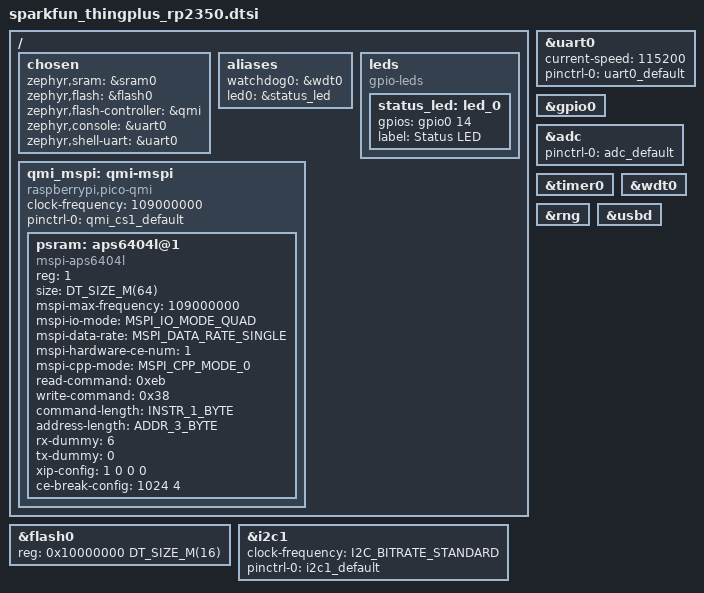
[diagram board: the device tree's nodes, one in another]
/*
 * SPDX-License-Identifier: Apache-2.0
 *
 * SparkFun Thing Plus RP2350 — common board configuration
 * (cpucluster-agnostic; included by both M33 and Hazard3 .dts files).
 */

#include <freq.h>
#include <zephyr/dt-bindings/i2c/i2c.h>
#include <zephyr/dt-bindings/pwm/pwm.h>
#include <zephyr/dt-bindings/gpio/gpio.h>

#include "sparkfun_thingplus_rp2350-pinctrl.dtsi"

/ {
	chosen {
		zephyr,sram = &sram0;
		zephyr,flash = &flash0;
		zephyr,flash-controller = &qmi;
		zephyr,console = &uart0;
		zephyr,shell-uart = &uart0;
	};

	aliases {
		watchdog0 = &wdt0;
		led0 = &status_led;
	};

	leds {
		compatible = "gpio-leds";
		status_led: led_0 {
			gpios = <&gpio0 14 GPIO_ACTIVE_HIGH>;
			label = "Status LED";
		};
	};
};

&flash0 {
	reg = <0x10000000 DT_SIZE_M(16)>;
};

&uart0 {
	current-speed = <115200>;
	status = "okay";
	pinctrl-0 = <&uart0_default>;
	pinctrl-names = "default";
};

&gpio0 {
	status = "okay";
};

&i2c1 {
	clock-frequency = <I2C_BITRATE_STANDARD>;
	pinctrl-0 = <&i2c1_default>;
	pinctrl-names = "default";
	status = "okay";
};

&adc {
	pinctrl-0 = <&adc_default>;
	pinctrl-names = "default";
	status = "okay";
};

&timer0 {
	status = "okay";
};

&wdt0 {
	status = "okay";
};

&rng {
	status = "okay";
};

zephyr_udc0: &usbd {
	status = "okay";
};

/*
 * On-board APS6404L 8 MiB pSRAM on QMI CS1.
 *
 * The QMI hardware peripheral is shared with the existing flash-controller
 * (CS0/m[0]); we expose CS1/m[1] as a separate MSPI bus. The driver uses
 * qmi_hw from the pico-sdk HAL, so this node does not consume reg — placing
 * it at the top level (rather than under &soc with a synthetic unit address)
 * avoids unit-address collision with the flash-controller @400d0000.
 *
 * The flash-controller and this MSPI controller never collide at runtime:
 * flash uses pico-sdk's flash_safe_execute discipline for direct-mode bursts,
 * and PSRAM bring-up runs once at POST_KERNEL before any flash writes are
 * possible.
 */
/ {
	qmi_mspi: qmi-mspi {
		compatible = "raspberrypi,pico-qmi";
		#address-cells = <1>;
		#size-cells = <0>;
		status = "okay";
		clock-frequency = <109000000>;

		pinctrl-0 = <&qmi_cs1_default>;
		pinctrl-names = "default";

		psram: aps6404l@1 {
			compatible = "mspi-aps6404l";
			reg = <1>;
			size = <DT_SIZE_M(64)>;       /* 64 Mbit = 8 MiB */
			mspi-max-frequency = <109000000>;
			mspi-io-mode = "MSPI_IO_MODE_QUAD";
			mspi-data-rate = "MSPI_DATA_RATE_SINGLE";
			mspi-hardware-ce-num = <1>;
			mspi-cpp-mode = "MSPI_CPP_MODE_0";
			read-command = <0xeb>;        /* APS6404L_QUAD_READ */
			write-command = <0x38>;       /* APS6404L_QUAD_WRITE */
			command-length = "INSTR_1_BYTE";
			address-length = "ADDR_3_BYTE";
			rx-dummy = <6>;
			tx-dummy = <0>;
			xip-config = <1 0 0 0>;
			ce-break-config = <1024 4>;
		};
	};
};
